VERSION ""

NS_ :

BS_:

BU_: Gateway_ECU Cluster_ECU PT_ECU

BO_ 514 frm_Window_Status: 1 Gateway_ECU
 SG_ sig_FR_Window_Status : 4|4@1+ (1,0) [0|15] ""  Cluster_ECU
 SG_ sig_FL_Window_Status : 0|4@1+ (1,0) [0|15] ""  Cluster_ECU

BO_ 513 frm_DT_Status: 1 Gateway_ECU
 SG_ sig_DT_Tunnel : 6|1@1+ (1,0) [0|1] ""  Cluster_ECU
 SG_ sig_DT_Now_Temp : 0|6@1+ (1,0) [0|63] ""  Cluster_ECU

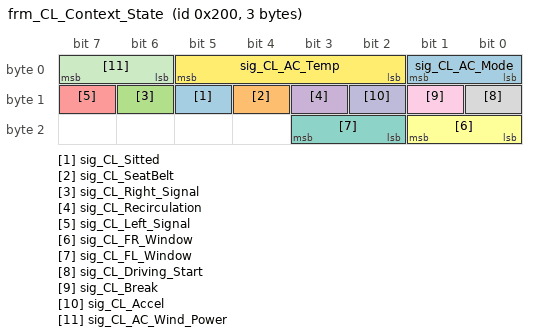
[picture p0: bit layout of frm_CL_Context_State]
BO_ 512 frm_CL_Context_State: 3 Cluster_ECU
 SG_ sig_CL_Sitted : 13|1@1+ (1,0) [0|1] ""  Gateway_ECU
 SG_ sig_CL_SeatBelt : 12|1@1+ (1,0) [0|1] ""  Gateway_ECU
 SG_ sig_CL_Right_Signal : 14|1@1+ (1,0) [0|0] ""  Gateway_ECU
 SG_ sig_CL_Recirculation : 11|1@1+ (1,0) [0|0] ""  Gateway_ECU
 SG_ sig_CL_Left_Signal : 15|1@1+ (1,0) [0|0] ""  Gateway_ECU
 SG_ sig_CL_FR_Window : 16|2@1+ (1,0) [0|0] ""  Gateway_ECU
 SG_ sig_CL_FL_Window : 18|2@1+ (1,0) [0|3] ""  Gateway_ECU
 SG_ sig_CL_Driving_Start : 8|1@1+ (1,0) [0|1] ""  Cluster_ECU,Gateway_ECU
 SG_ sig_CL_Break : 9|1@1+ (1,0) [0|0] ""  Gateway_ECU,Cluster_ECU
 SG_ sig_CL_Accel : 10|1@1+ (1,0) [0|1] ""  Gateway_ECU,Cluster_ECU
 SG_ sig_CL_AC_Wind_Power : 6|2@1+ (1,1) [1|4] ""  Gateway_ECU
 SG_ sig_CL_AC_Temp : 2|4@1+ (1,18) [18|33] ""  Gateway_ECU
 SG_ sig_CL_AC_Mode : 0|2@1+ (1,0) [0|0] ""  Gateway_ECU

BO_ 256 frm_Engine_Status: 2 PT_ECU
 SG_ sig_Engine_RPM : 0|13@1+ (1,0) [0|8191] "RPM"  Gateway_ECU

BA_DEF_  "BusType" STRING ;
BA_DEF_DEF_  "BusType" "CAN";
